# S6E2C4 register map
File version: 1.0
Registers are 32-bit, read-write, reset 0x0 unless marked. A register's access mark holds for its fields unless they carry their own. Offsets are from the block's base; [hi:lo] are bit positions; {n}, {i} and the like mark numbered series.

## DS — Low Power Consumption Mode
Base 0x40035100
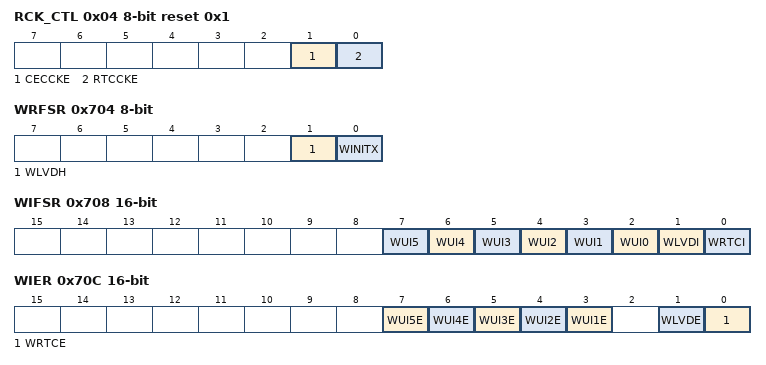
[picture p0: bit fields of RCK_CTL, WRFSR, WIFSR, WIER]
0x04 RCK_CTL 8-bit reset 0x1 — Sub Clock Control Register
  [1] CECCKE — CEC clock control bit
  [0] RTCCKE — RTC clock control bit
0x700 PMD_CTL 8-bit — RTC Mode Control Register
  [0] RTCE — RTC mode control bit
0x704 WRFSR 8-bit — Deep Standby Return Cause Register 1
  [1] WLVDH — Low-voltage detection reset return bit
  [0] WINITX — INITX pin input reset return bit
0x708 WIFSR 16-bit ro — Deep Standby Return Cause Register 2
  [n+2] WUI{n} (n=0..5) — WKUP pin input return bit {n}
  [1] WLVDI — LVD interrupt return bit
  [0] WRTCI — RTC interrupt return bit
0x70C WIER 16-bit — Deep Standby Return Enable Register
  [n+2] WUI{n}E (n=1..5) — WKUP pin input return enable bit {n}
  [1] WLVDE — LVD interrupt return enable bit
  [0] WRTCE — RTC interrupt return enable bit
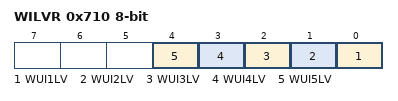
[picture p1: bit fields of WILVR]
0x710 WILVR 8-bit — WKUP Pin Input Level Register
  [n-1] WUI{n}LV (n=1..5) — WKUP pin input level select bit {n}
0x714 DSRAMR 8-bit — Deep Standby RAM Retention Register
  [1:0] SRAMR — On-chip SRAM retention control bits
{0x7FF+i} BUR{i:02} 8-bit (i=1..16) — Backup Registers from {i}

## CRC — CRC Registers
Base 0x40039000
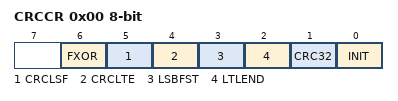
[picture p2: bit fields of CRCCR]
0x00 CRCCR 8-bit — CRC Control Register
  [6] FXOR — Initialization bit
  [5] CRCLSF — Final XOR control bit
  [4] CRCLTE — CRC result bit-order setting bit
  [3] LSBFST — CRC result byte-order setting bit
  [2] LTLEND — Bit-order setting bit
  [1] CRC32 — Byte-order setting bit
  [0] INIT — CRC mode selection bit
0x04 CRCINIT reset 0xFFFFFFFF — Initial Value Register
  [31:0] D — Initial value
0x08 CRCIN — Input Data Register
  [31:0] D — Input data
0x0C CRCR ro reset 0xFFFFFFFF — CRC Register
  [31:0] D — CRC Data

## WC — Watch Counter
Base 0x4003A000
0x00 WCRD 8-bit ro — Watch Counter Read Register
  [5:0] CTR — Counter read bits
0x01 WCRL 8-bit — Watch Counter Reload Register
  [5:0] RLC — Counter reload value setting bits
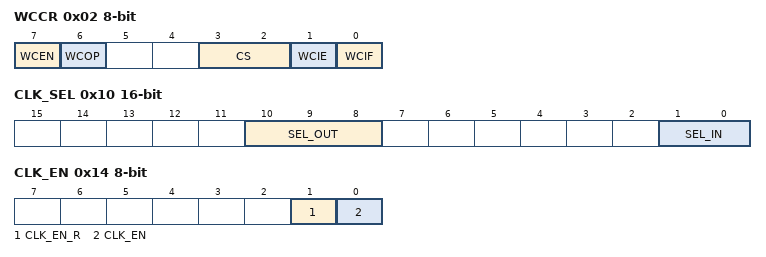
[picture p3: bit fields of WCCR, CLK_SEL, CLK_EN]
0x02 WCCR 8-bit — Watch Counter Control Register
  [7] WCEN — Watch counter operation enable bit
  [6] WCOP ro — Watch counter operating state flag
  [3:2] CS — Count clock select bits
  [1] WCIE — Interrupt request enable bit
  [0] WCIF — Interrupt request flag bit
0x10 CLK_SEL 16-bit — Clock Selection Register
  [10:8] SEL_OUT — Output clock selection bit
  [1:0] SEL_IN — Input clock selection bit
0x14 CLK_EN 8-bit — Division Clock Enable Register
  [1] CLK_EN_R — Division clock enable read bit
  [0] CLK_EN — Division clock enable bit

## LCR — Low-speed CR Prescaler
Base 0x4003C000
0x00 LCR_PRSLD 8-bit — Low-speed CR Prescaler Control Register
  [5:0] LCR_PRSLD — Low-speed CR Prescaler Load

## PLL_CONTROL — Main PLL Control
Base 0x4003C800
0x00 SSCTL1 (reset mask 0x31)
0x04 SSCTL2 (reset mask 0x3FF)

## EXBUS — External Bus Interface
Base 0x4003F000
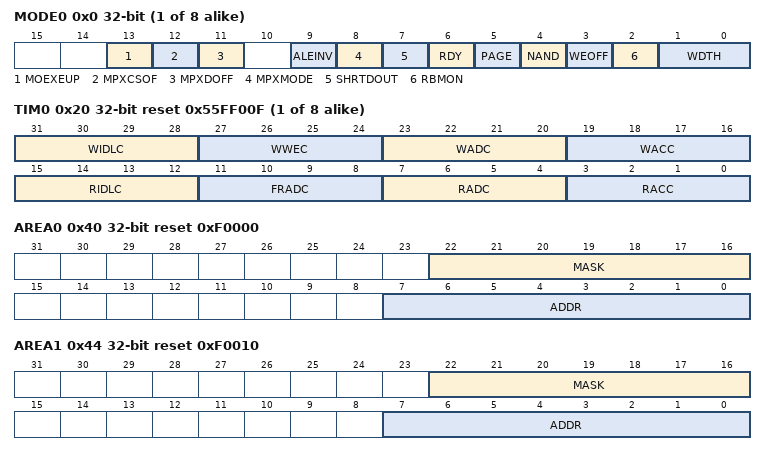
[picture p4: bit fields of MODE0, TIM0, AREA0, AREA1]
{0x0+4i} MODE{i} (i=0..7) — Mode Register {i}
  [13] MOEXEUP — select how to set the MOEX width
  [12] MPXCSOF — select a CS assertion from the start of accessing to the end of address output
  [11] MPXDOFF — select whether or not the address is output to the data lines in multiplex mode
  [9] ALEINV — set up the polarity of the ALE signal
  [8] MPXMODE — select operation bus mode
  [7] SHRTDOUT — select to which idle cycle the write data output is extended
  [6] RDY — control the external RDY function
  [5] PAGE — NOR Flash memory page access mode
  [4] NAND — NAND Flash memory mode
  [3] WEOFF — disable the write enable signal (MWEX) operation
  [2] RBMON — Read Byte Mask ON
  [1:0] WDTH — specify Data Width
{0x20+4i} TIM{i} reset 0x55FF00F (i=0..7) — Timing Register {i}
  [31:28] WIDLC — Write Idle Cycle
  [27:24] WWEC — Write Enable Cycle
  [23:20] WADC — Write Address Setup cycle
  [19:16] WACC — Write Access Cycle
  [15:12] RIDLC — Read Idle Cycle
  [11:8] FRADC — First Read Address Cycle
  [7:4] RADC — Read Address Setup cycle
  [3:0] RACC — Read Access Cycle
0x40 AREA0 reset 0xF0000 — Area Register 0
  [22:16] MASK — address mask
  [7:0] ADDR — Address
0x44 AREA1 reset 0xF0010 — Area Register 1
  [22:16] MASK — address mask
  [7:0] ADDR — Address
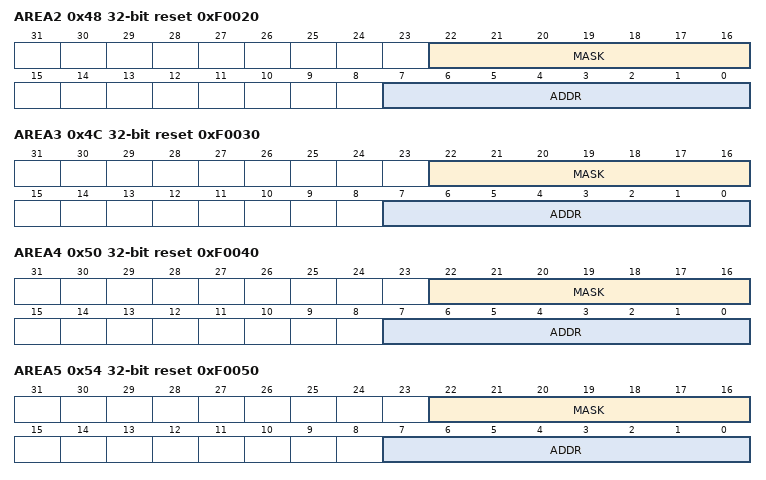
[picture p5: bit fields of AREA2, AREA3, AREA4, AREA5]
0x48 AREA2 reset 0xF0020 — Area Register 2
  [22:16] MASK — address mask
  [7:0] ADDR — Address
0x4C AREA3 reset 0xF0030 — Area Register 3
  [22:16] MASK — address mask
  [7:0] ADDR — Address
0x50 AREA4 reset 0xF0040 — Area Register 4
  [22:16] MASK — address mask
  [7:0] ADDR — Address
0x54 AREA5 reset 0xF0050 — Area Register 5
  [22:16] MASK — address mask
  [7:0] ADDR — Address
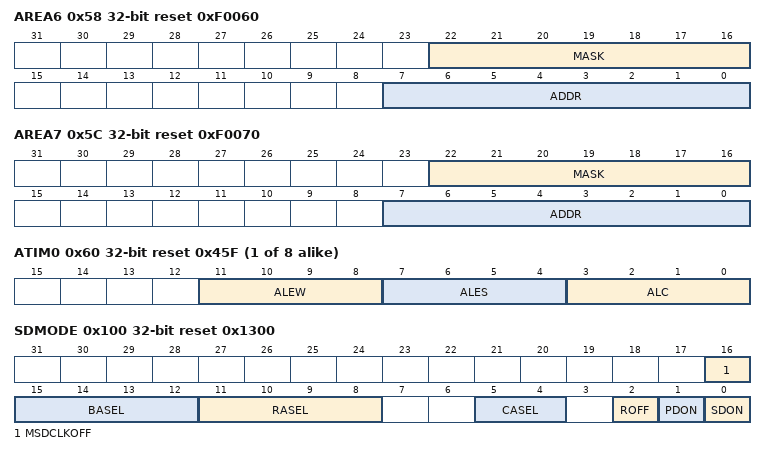
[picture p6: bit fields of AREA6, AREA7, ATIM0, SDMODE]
0x58 AREA6 reset 0xF0060 — Area Register 6
  [22:16] MASK — address mask
  [7:0] ADDR — Address
0x5C AREA7 reset 0xF0070 — Area Register 7
  [22:16] MASK — address mask
  [7:0] ADDR — Address
{0x60+4i} ATIM{i} reset 0x45F (i=0..7) — ALE Timing Register {i}
  [11:8] ALEW — Address Latch Enable Width
  [7:4] ALES — Address Latch Enable Setup cycle
  [3:0] ALC — Address Latch Cycle
0x100 SDMODE reset 0x1300 — SDRAM Mode Register
  [16] MSDCLKOFF
  [15:12] BASEL — Bank Address Select
  [11:8] RASEL — Row Address Select
  [5:4] CASEL — Column Address Select
  [2] ROFF — Refresh OFF
  [1] PDON — Power Down ON
  [0] SDON — SDRAM ON
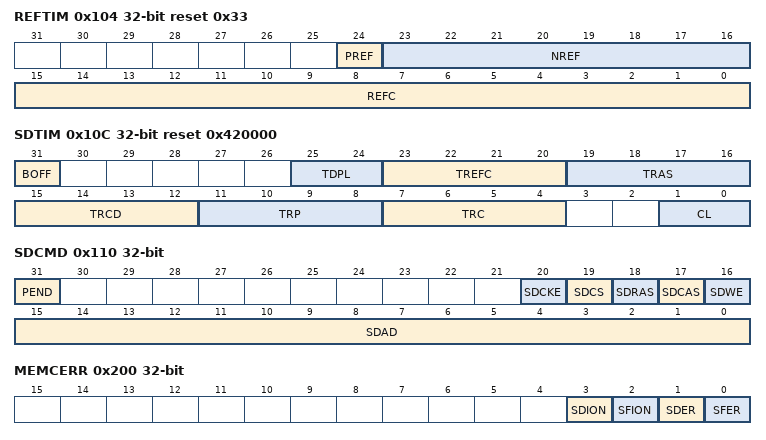
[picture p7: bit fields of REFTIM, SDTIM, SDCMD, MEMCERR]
0x104 REFTIM reset 0x33 — Refresh Timer Register
  [24] PREF — Pre-Refresh
  [23:16] NREF — Number of Refresh
  [15:0] REFC — Refresh Count
0x108 PWRDWN — Power Down Count Register
  [15:0] PDC — Power Down Count
0x10C SDTIM reset 0x420000 — SDRAM Timing Register
  [31] BOFF — Buffer readout bit
  [25:24] TDPL — Data-in to Precharge Lead Time
  [23:20] TREFC — Refresh Cycle time
  [19:16] TRAS — RAS active time
  [15:12] TRCD — RAS-CAS Delay
  [11:8] TRP — RAS Precharge time
  [7:4] TRC — RAS Cycle time
  [1:0] CL — CAS Latency
0x110 SDCMD — SDRAM Command Register
  [31] PEND ro
  [20] SDCKE — SDRAM CKE
  [19] SDCS — SDRAM Chip Select
  [18] SDRAS — SDRAM RAS
  [17] SDCAS — SDRAM CAS
  [16] SDWE — SDRAM Write Enable
  [15:0] SDAD — SDRAM ADress
0x200 MEMCERR — Memory Controller Register
  [3] SDION — SDRAM error Interrupt ON
  [2] SFION — SRAM/Flash error Interrupt ON
  [1] SDER — SDRAM Error
  [0] SFER — SRAM/Flash Error
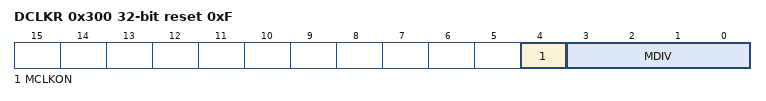
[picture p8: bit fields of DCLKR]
0x300 DCLKR reset 0xF — Division Clock Register
  [4] MCLKON
  [3:0] MDIV — MCLK Division Ratio Setup
0x304 EST ro — Error Status Register
  [0] WERR
0x308 WEAD ro — Write Error Address Register
  [31:0] ADDR
0x30C ESCLR wo reset 0x1 — Error Status Clear Register
  [0] WERRCLR — Write Error Clear
0x310 AMODE reset 0x1 — Access Mode Register
  [0] WAEN
